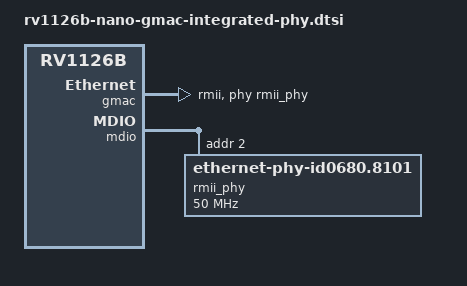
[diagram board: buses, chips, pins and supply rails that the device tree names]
// SPDX-License-Identifier: (GPL-2.0+ OR MIT)
/*
 * Copyright (c) 2025 Guangzhou EASY EAI Technology Co., Ltd.
 */

&gmac {
	phy-mode = "rmii";
	clock_in_out = "input";
	phy-handle = <&rmii_phy>;
	status = "okay";
};

&mdio {
	rmii_phy: ethernet-phy@2 {
		compatible = "ethernet-phy-id0680.8101", "ethernet-phy-ieee802.3-c22";
		reg = <2>;
		clocks = <&cru CLK_MACPHY>;
		clock-frequency = <50000000>;
		resets = <&cru SRST_RESETN_MACPHY>;
		pinctrl-names = "default";
		pinctrl-0 = <&fephym1_pins>;
		phy-is-integrated;
	};
};
